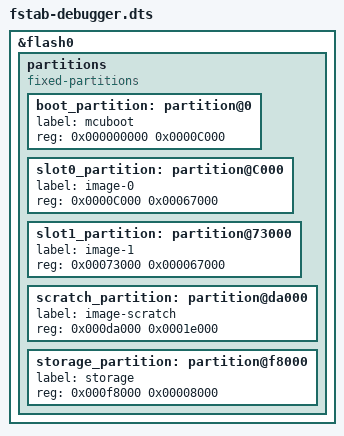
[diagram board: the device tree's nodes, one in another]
/*
 * Copyright (c) 2019 Nordic Semiconductor ASA
 *
 * SPDX-License-Identifier: Apache-2.0
 */

/* Flash partition table without support for Nordic nRF5 bootloader */

&flash0 {
	partitions {
		compatible = "fixed-partitions";
		#address-cells = <1>;
		#size-cells = <1>;

		boot_partition: partition@0 {
			label = "mcuboot";
			reg = <0x000000000 0x0000C000>;
		};

		slot0_partition: partition@C000 {
			label = "image-0";
			reg = <0x0000C000 0x00067000>;
		};
		slot1_partition: partition@73000 {
			label = "image-1";
			reg = <0x00073000 0x000067000>;
		};
		scratch_partition: partition@da000 {
			label = "image-scratch";
			reg = <0x000da000 0x0001e000>;
		};
		storage_partition: partition@f8000 {
			label = "storage";
			reg = <0x000f8000 0x00008000>;
		};
	};
};
